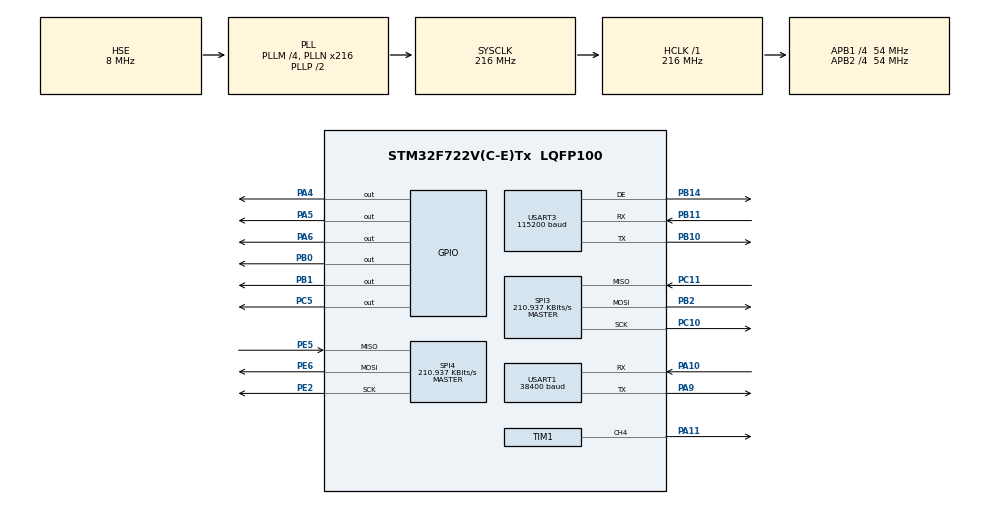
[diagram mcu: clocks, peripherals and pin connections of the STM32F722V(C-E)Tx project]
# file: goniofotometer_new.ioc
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Dma.Request0=USART3_RX
Dma.Request1=USART1_RX
Dma.Request2=SPI4_RX
Dma.Request3=SPI4_TX
Dma.Request4=SPI3_RX
Dma.Request5=SPI3_TX
Dma.SPI3_RX.4.Direction=DMA_PERIPH_TO_MEMORY
Dma.SPI3_RX.4.FIFOMode=DMA_FIFOMODE_DISABLE
Dma.SPI3_RX.4.Instance=DMA1_Stream0
Dma.SPI3_RX.4.MemDataAlignment=DMA_MDATAALIGN_BYTE
Dma.SPI3_RX.4.MemInc=DMA_MINC_ENABLE
Dma.SPI3_RX.4.Mode=DMA_NORMAL
Dma.SPI3_RX.4.PeriphDataAlignment=DMA_PDATAALIGN_BYTE
Dma.SPI3_RX.4.PeriphInc=DMA_PINC_DISABLE
Dma.SPI3_RX.4.Priority=DMA_PRIORITY_LOW
Dma.SPI3_TX.5.Direction=DMA_MEMORY_TO_PERIPH
Dma.SPI3_TX.5.FIFOMode=DMA_FIFOMODE_DISABLE
Dma.SPI3_TX.5.Instance=DMA1_Stream5
Dma.SPI3_TX.5.MemDataAlignment=DMA_MDATAALIGN_BYTE
Dma.SPI3_TX.5.MemInc=DMA_MINC_ENABLE
Dma.SPI3_TX.5.Mode=DMA_NORMAL
Dma.SPI3_TX.5.PeriphDataAlignment=DMA_PDATAALIGN_BYTE
Dma.SPI3_TX.5.PeriphInc=DMA_PINC_DISABLE
Dma.SPI3_TX.5.Priority=DMA_PRIORITY_LOW
Dma.SPI4_RX.2.Direction=DMA_PERIPH_TO_MEMORY
Dma.SPI4_RX.2.FIFOMode=DMA_FIFOMODE_DISABLE
Dma.SPI4_RX.2.Instance=DMA2_Stream0
Dma.SPI4_RX.2.MemDataAlignment=DMA_MDATAALIGN_BYTE
Dma.SPI4_RX.2.MemInc=DMA_MINC_ENABLE
Dma.SPI4_RX.2.Mode=DMA_NORMAL
Dma.SPI4_RX.2.PeriphDataAlignment=DMA_PDATAALIGN_BYTE
Dma.SPI4_RX.2.PeriphInc=DMA_PINC_DISABLE
Dma.SPI4_RX.2.Priority=DMA_PRIORITY_LOW
Dma.SPI4_TX.3.Direction=DMA_MEMORY_TO_PERIPH
Dma.SPI4_TX.3.FIFOMode=DMA_FIFOMODE_DISABLE
Dma.SPI4_TX.3.Instance=DMA2_Stream1
Dma.SPI4_TX.3.MemDataAlignment=DMA_MDATAALIGN_BYTE
Dma.SPI4_TX.3.MemInc=DMA_MINC_ENABLE
Dma.SPI4_TX.3.Mode=DMA_NORMAL
Dma.SPI4_TX.3.PeriphDataAlignment=DMA_PDATAALIGN_BYTE
Dma.SPI4_TX.3.PeriphInc=DMA_PINC_DISABLE
Dma.SPI4_TX.3.Priority=DMA_PRIORITY_LOW
Dma.USART1_RX.1.Direction=DMA_PERIPH_TO_MEMORY
Dma.USART1_RX.1.FIFOMode=DMA_FIFOMODE_DISABLE
Dma.USART1_RX.1.Instance=DMA2_Stream2
Dma.USART1_RX.1.MemDataAlignment=DMA_MDATAALIGN_BYTE
Dma.USART1_RX.1.MemInc=DMA_MINC_ENABLE
Dma.USART1_RX.1.Mode=DMA_NORMAL
Dma.USART1_RX.1.PeriphDataAlignment=DMA_PDATAALIGN_BYTE
Dma.USART1_RX.1.PeriphInc=DMA_PINC_DISABLE
Dma.USART1_RX.1.Priority=DMA_PRIORITY_HIGH
Dma.USART3_RX.0.Direction=DMA_PERIPH_TO_MEMORY
Dma.USART3_RX.0.FIFOMode=DMA_FIFOMODE_DISABLE
Dma.USART3_RX.0.Instance=DMA1_Stream1
Dma.USART3_RX.0.MemDataAlignment=DMA_MDATAALIGN_BYTE
Dma.USART3_RX.0.MemInc=DMA_MINC_ENABLE
Dma.USART3_RX.0.Mode=DMA_CIRCULAR
Dma.USART3_RX.0.PeriphDataAlignment=DMA_PDATAALIGN_BYTE
Dma.USART3_RX.0.PeriphInc=DMA_PINC_DISABLE
Dma.USART3_RX.0.Priority=DMA_PRIORITY_LOW
IWDG.Prescaler=IWDG_PRESCALER_16
Mcu.Family=STM32F7
Mcu.Name=STM32F722V(C-E)Tx
Mcu.Package=LQFP100
NVIC.DMA1_Stream0_IRQn=true\:1\:0\:true\:false\:true\:false\:true\:true
NVIC.DMA1_Stream1_IRQn=true\:1\:0\:true\:false\:true\:false\:true\:true
NVIC.DMA1_Stream5_IRQn=true\:1\:0\:true\:false\:true\:false\:true\:true
NVIC.DMA2_Stream0_IRQn=true\:1\:1\:true\:false\:true\:false\:true\:true
NVIC.DMA2_Stream1_IRQn=true\:1\:1\:true\:false\:true\:false\:true\:true
NVIC.DMA2_Stream2_IRQn=true\:1\:0\:true\:false\:true\:false\:true\:true
NVIC.PriorityGroup=NVIC_PRIORITYGROUP_2
NVIC.TIM1_TRG_COM_TIM11_IRQn=true\:1\:3\:true\:false\:true\:true\:true\:true
NVIC.TIM1_UP_TIM10_IRQn=true\:3\:3\:true\:false\:true\:true\:true\:true
NVIC.TIM2_IRQn=true\:2\:0\:true\:false\:true\:true\:true\:true
NVIC.TIM3_IRQn=true\:2\:0\:true\:false\:true\:true\:true\:true
NVIC.TIM4_IRQn=true\:0\:0\:false\:false\:true\:true\:true\:true
NVIC.TIM5_IRQn=true\:1\:0\:true\:false\:true\:true\:true\:true
NVIC.TIM7_IRQn=true\:2\:0\:true\:false\:true\:true\:true\:true
NVIC.TIM8_BRK_TIM12_IRQn=true\:1\:3\:true\:false\:true\:true\:true\:true
NVIC.TIM8_TRG_COM_TIM14_IRQn=true\:1\:1\:true\:false\:true\:true\:true\:true
NVIC.TIM8_UP_TIM13_IRQn=true\:1\:1\:true\:false\:true\:true\:true\:true
NVIC.USART1_IRQn=true\:1\:0\:true\:false\:true\:true\:true\:true
NVIC.USART3_IRQn=true\:1\:0\:true\:false\:true\:true\:true\:true
PA10.Mode=Asynchronous
PA10.Signal=USART1_RX
PA11.Signal=S_TIM1_CH4
PA13.Mode=Serial_Wire
PA13.Signal=SYS_JTMS-SWDIO
PA14.Mode=Serial_Wire
PA14.Signal=SYS_JTCK-SWCLK
PA4.Signal=GPIO_Output
PA5.Signal=GPIO_Output
PA6.Signal=GPIO_Output
PA9.Mode=Asynchronous
PA9.Signal=USART1_TX
PB0.Signal=GPIO_Output
PB1.Signal=GPIO_Output
PB10.Mode=Asynchronous
PB10.Signal=USART3_TX
PB11.Mode=Asynchronous
PB11.Signal=USART3_RX
PB14.Mode=Hardware Flow Control (RS485)
PB14.Signal=USART3_DE
PB2.Mode=Full_Duplex_Master
PB2.Signal=SPI3_MOSI
PC10.Mode=Full_Duplex_Master
PC10.Signal=SPI3_SCK
PC11.Mode=Full_Duplex_Master
PC11.Signal=SPI3_MISO
PC5.Signal=GPIO_Output
PE2.Mode=Full_Duplex_Master
PE2.Signal=SPI4_SCK
PE5.Mode=Full_Duplex_Master
PE5.Signal=SPI4_MISO
PE6.Mode=Full_Duplex_Master
PE6.Signal=SPI4_MOSI
PH0-OSC_IN.Mode=HSE-External-Oscillator
PH0-OSC_IN.Signal=RCC_OSC_IN
PH1-OSC_OUT.Mode=HSE-External-Oscillator
PH1-OSC_OUT.Signal=RCC_OSC_OUT
ProjectManager.HeapSize=0x200
ProjectManager.StackSize=0x400
ProjectManager.TargetToolchain=STM32CubeIDE
RCC.AHBFreq_Value=216000000
RCC.APB1CLKDivider=RCC_HCLK_DIV4
RCC.APB1Freq_Value=54000000
RCC.APB1TimFreq_Value=108000000
RCC.APB2CLKDivider=RCC_HCLK_DIV4
RCC.APB2Freq_Value=54000000
RCC.APB2TimFreq_Value=108000000
RCC.CortexFreq_Value=216000000
RCC.HCLKFreq_Value=216000000
RCC.HSE_VALUE=8000000
RCC.HSI_VALUE=16000000
RCC.LSE_VALUE=32768
RCC.PLLM=4
RCC.PLLN=216
RCC.PLLSourceVirtual=RCC_PLLSOURCE_HSE
RCC.SYSCLKFreq_VALUE=216000000
RCC.SYSCLKSource=RCC_SYSCLKSOURCE_PLLCLK
RCC.USBFreq_Value=216000000
RCC.VCOOutputFreq_Value=432000000
SH.S_TIM1_CH4.0=TIM1_CH4,PWM Generation4 CH4
SPI3.BaudRatePrescaler=SPI_BAUDRATEPRESCALER_256
SPI3.CLKPolarity=SPI_POLARITY_HIGH
SPI3.CalculateBaudRate=210.937 KBits/s
SPI3.DataSize=SPI_DATASIZE_8BIT
SPI3.Direction=SPI_DIRECTION_2LINES
SPI3.Mode=SPI_MODE_MASTER
SPI3.VirtualType=VM_MASTER
SPI4.BaudRatePrescaler=SPI_BAUDRATEPRESCALER_256
SPI4.CLKPolarity=SPI_POLARITY_HIGH
SPI4.CalculateBaudRate=210.937 KBits/s
SPI4.DataSize=SPI_DATASIZE_8BIT
SPI4.Direction=SPI_DIRECTION_2LINES
SPI4.Mode=SPI_MODE_MASTER
SPI4.VirtualType=VM_MASTER
TIM1.Channel-PWM\ Generation4\ CH4=TIM_CHANNEL_4
TIM1.OCPolarity_4=TIM_OCPOLARITY_LOW
TIM1.Period=21
TIM1.Prescaler=107
TIM1.Pulse-PWM\ Generation4\ CH4=1
TIM10.Period=65535
TIM10.Prescaler=21599
TIM11.Period=30000
TIM11.Prescaler=10799
TIM12.Period=500
TIM12.Prescaler=10799
TIM13.Prescaler=1079
TIM14.Prescaler=21599
TIM2.Period=24999
TIM2.Prescaler=107
TIM3.Period=15999
TIM3.Prescaler=1079
TIM4.Period=200
TIM4.Prescaler=10799
TIM5.Prescaler=10799
TIM6.Prescaler=107
TIM7.Period=99
TIM7.Prescaler=107
USART1.BaudRate=38400
USART1.VirtualMode-Asynchronous=VM_ASYNC
USART3.BaudRate=115200
USART3.VirtualMode-Asynchronous=VM_ASYNC
USART3.VirtualMode-Hardware\ Flow\ Control\ (RS485)=VM_ASYNC
VP_IWDG_VS_IWDG.Mode=IWDG_Activate
VP_TIM10_VS_ClockSourceINT.Mode=Enable_Timer
VP_TIM11_VS_ClockSourceINT.Mode=Enable_Timer
VP_TIM12_VS_ClockSourceINT.Mode=Internal
VP_TIM13_VS_ClockSourceINT.Mode=Enable_Timer
VP_TIM14_VS_ClockSourceINT.Mode=Enable_Timer
VP_TIM1_VS_ClockSourceINT.Mode=Internal
VP_TIM1_VS_OPM.Mode=OPM_bit
VP_TIM2_VS_ClockSourceINT.Mode=Internal
VP_TIM3_VS_ClockSourceINT.Mode=Internal
VP_TIM4_VS_ClockSourceINT.Mode=Internal
VP_TIM5_VS_ClockSourceINT.Mode=Internal
VP_TIM6_VS_ClockSourceINT.Mode=Enable_Timer
VP_TIM7_VS_ClockSourceINT.Mode=Enable_Timer
board=custom

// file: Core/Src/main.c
/* USER CODE BEGIN Header */
/**
  ******************************************************************************
  * @file           : main.c
  * @brief          : Main program body
  ******************************************************************************
  * @attention
  *
  * Copyright (c) 2026 STMicroelectronics.
  * All rights reserved.
  *
  * This software is licensed under terms that can be found in the LICENSE file
  * in the root directory of this software component.
  * If no LICENSE file comes with this software, it is provided AS-IS.
  *
  ******************************************************************************
  */
/* USER CODE END Header */
#include "main.h"

/* USER CODE BEGIN Includes */
#include "Common.h"
#include "FSMGonio.h"
/* USER CODE END Includes */

IWDG_HandleTypeDef hiwdg;

SPI_HandleTypeDef hspi3;
SPI_HandleTypeDef hspi4;
DMA_HandleTypeDef hdma_spi3_rx;
DMA_HandleTypeDef hdma_spi3_tx;
DMA_HandleTypeDef hdma_spi4_rx;
DMA_HandleTypeDef hdma_spi4_tx;

TIM_HandleTypeDef htim1;
TIM_HandleTypeDef htim2;
TIM_HandleTypeDef htim3;
TIM_HandleTypeDef htim4;
TIM_HandleTypeDef htim5;
TIM_HandleTypeDef htim6;
TIM_HandleTypeDef htim7;
TIM_HandleTypeDef htim10;
TIM_HandleTypeDef htim11;
TIM_HandleTypeDef htim12;
TIM_HandleTypeDef htim13;
TIM_HandleTypeDef htim14;

UART_HandleTypeDef huart1;
UART_HandleTypeDef huart3;
DMA_HandleTypeDef hdma_usart1_rx;
DMA_HandleTypeDef hdma_usart3_rx;

void SystemClock_Config(void);
static void MX_GPIO_Init(void);
static void MX_DMA_Init(void);
static void MX_USART3_UART_Init(void);
static void MX_USART1_UART_Init(void);
static void MX_SPI4_Init(void);
static void MX_SPI3_Init(void);
static void MX_TIM2_Init(void);
static void MX_TIM3_Init(void);
static void MX_TIM6_Init(void);
static void MX_TIM7_Init(void);
static void MX_TIM10_Init(void);
static void MX_TIM5_Init(void);
static void MX_TIM14_Init(void);
static void MX_TIM13_Init(void);
static void MX_TIM4_Init(void);
static void MX_TIM11_Init(void);
static void MX_TIM12_Init(void);
static void MX_IWDG_Init(void);
static void MX_TIM1_Init(void);

/* USER CODE BEGIN 0 */
void resetWatchDogTimer() {
	HAL_IWDG_Refresh(&hiwdg);
}
/* USER CODE END 0 */

int main(void)
{

  /* MCU Configuration--------------------------------------------------------*/

  /* Reset of all peripherals, Initializes the Flash interface and the Systick. */
  HAL_Init();

  /* Configure the system clock */
  SystemClock_Config();

  /* Initialize all configured peripherals */
  MX_GPIO_Init();
  MX_DMA_Init();
  MX_USART3_UART_Init();
  MX_USART1_UART_Init();
  MX_SPI4_Init();
  MX_SPI3_Init();
  MX_TIM2_Init();
  MX_TIM3_Init();
  MX_TIM6_Init();
  MX_TIM7_Init();
  MX_TIM10_Init();
  MX_TIM5_Init();
  MX_TIM14_Init();
  MX_TIM13_Init();
  MX_TIM4_Init();
  MX_TIM11_Init();
  MX_TIM12_Init();
  MX_IWDG_Init();
  MX_TIM1_Init();
  /* USER CODE BEGIN 2 */
  initFSMGonio();
  /* USER CODE END 2 */

  /* Infinite loop */
  /* USER CODE BEGIN WHILE */
  while (1)
  {
	// обновление сторожевого таймера
	resetWatchDogTimer();

	// вход в диспетчер машины состояний
	dispatchFSMGlobal();

	// проверка keep-alive таймера
	if (tim11_ovflw) {
		resetGonio();
		tim11_ovflw = 0;
	}

    /* USER CODE END WHILE */

  }
}

void SystemClock_Config(void)
{
  RCC_OscInitTypeDef RCC_OscInitStruct = {0};
  RCC_ClkInitTypeDef RCC_ClkInitStruct = {0};

  /** Configure the main internal regulator output voltage
  */
  __HAL_RCC_PWR_CLK_ENABLE();
  __HAL_PWR_VOLTAGESCALING_CONFIG(PWR_REGULATOR_VOLTAGE_SCALE1);

  /** Initializes the RCC Oscillators according to the specified parameters
  * in the RCC_OscInitTypeDef structure.
  */
  RCC_OscInitStruct.OscillatorType = RCC_OSCILLATORTYPE_LSI|RCC_OSCILLATORTYPE_HSE;
  RCC_OscInitStruct.HSEState = RCC_HSE_ON;
  RCC_OscInitStruct.LSIState = RCC_LSI_ON;
  RCC_OscInitStruct.PLL.PLLState = RCC_PLL_ON;
  RCC_OscInitStruct.PLL.PLLSource = RCC_PLLSOURCE_HSE;
  RCC_OscInitStruct.PLL.PLLM = 4;
  RCC_OscInitStruct.PLL.PLLN = 216;
  RCC_OscInitStruct.PLL.PLLP = RCC_PLLP_DIV2;
  RCC_OscInitStruct.PLL.PLLQ = 2;
  if (HAL_RCC_OscConfig(&RCC_OscInitStruct) != HAL_OK)
  {
    Error_Handler();
  }

  /** Activate the Over-Drive mode
  */
  if (HAL_PWREx_EnableOverDrive() != HAL_OK)
  {
    Error_Handler();
  }

  /** Initializes the CPU, AHB and APB buses clocks
  */
  RCC_ClkInitStruct.ClockType = RCC_CLOCKTYPE_HCLK|RCC_CLOCKTYPE_SYSCLK
                              |RCC_CLOCKTYPE_PCLK1|RCC_CLOCKTYPE_PCLK2;
  RCC_ClkInitStruct.SYSCLKSource = RCC_SYSCLKSOURCE_PLLCLK;
  RCC_ClkInitStruct.AHBCLKDivider = RCC_SYSCLK_DIV1;
  RCC_ClkInitStruct.APB1CLKDivider = RCC_HCLK_DIV4;
  RCC_ClkInitStruct.APB2CLKDivider = RCC_HCLK_DIV4;

  if (HAL_RCC_ClockConfig(&RCC_ClkInitStruct, FLASH_LATENCY_7) != HAL_OK)
  {
    Error_Handler();
  }
}

static void MX_IWDG_Init(void)
{

  hiwdg.Instance = IWDG;
  hiwdg.Init.Prescaler = IWDG_PRESCALER_16;
  hiwdg.Init.Window = 4095;
  hiwdg.Init.Reload = 4095;
  if (HAL_IWDG_Init(&hiwdg) != HAL_OK)
  {
    Error_Handler();
  }

}

static void MX_SPI3_Init(void)
{

  /* SPI3 parameter configuration*/
  hspi3.Instance = SPI3;
  hspi3.Init.Mode = SPI_MODE_MASTER;
  hspi3.Init.Direction = SPI_DIRECTION_2LINES;
  hspi3.Init.DataSize = SPI_DATASIZE_8BIT;
  hspi3.Init.CLKPolarity = SPI_POLARITY_HIGH;
  hspi3.Init.CLKPhase = SPI_PHASE_1EDGE;
  hspi3.Init.NSS = SPI_NSS_SOFT;
  hspi3.Init.BaudRatePrescaler = SPI_BAUDRATEPRESCALER_256;
  hspi3.Init.FirstBit = SPI_FIRSTBIT_MSB;
  hspi3.Init.TIMode = SPI_TIMODE_DISABLE;
  hspi3.Init.CRCCalculation = SPI_CRCCALCULATION_DISABLE;
  hspi3.Init.CRCPolynomial = 7;
  hspi3.Init.CRCLength = SPI_CRC_LENGTH_DATASIZE;
  hspi3.Init.NSSPMode = SPI_NSS_PULSE_ENABLE;
  if (HAL_SPI_Init(&hspi3) != HAL_OK)
  {
    Error_Handler();
  }

}

static void MX_SPI4_Init(void)
{

  /* SPI4 parameter configuration*/
  hspi4.Instance = SPI4;
  hspi4.Init.Mode = SPI_MODE_MASTER;
  hspi4.Init.Direction = SPI_DIRECTION_2LINES;
  hspi4.Init.DataSize = SPI_DATASIZE_8BIT;
  hspi4.Init.CLKPolarity = SPI_POLARITY_HIGH;
  hspi4.Init.CLKPhase = SPI_PHASE_1EDGE;
  hspi4.Init.NSS = SPI_NSS_SOFT;
  hspi4.Init.BaudRatePrescaler = SPI_BAUDRATEPRESCALER_256;
  hspi4.Init.FirstBit = SPI_FIRSTBIT_MSB;
  hspi4.Init.TIMode = SPI_TIMODE_DISABLE;
  hspi4.Init.CRCCalculation = SPI_CRCCALCULATION_DISABLE;
  hspi4.Init.CRCPolynomial = 7;
  hspi4.Init.CRCLength = SPI_CRC_LENGTH_DATASIZE;
  hspi4.Init.NSSPMode = SPI_NSS_PULSE_ENABLE;
  if (HAL_SPI_Init(&hspi4) != HAL_OK)
  {
    Error_Handler();
  }

}

static void MX_TIM1_Init(void)
{

  TIM_ClockConfigTypeDef sClockSourceConfig = {0};
  TIM_MasterConfigTypeDef sMasterConfig = {0};
  TIM_OC_InitTypeDef sConfigOC = {0};
  TIM_BreakDeadTimeConfigTypeDef sBreakDeadTimeConfig = {0};

  htim1.Instance = TIM1;
  htim1.Init.Prescaler = 107;
  htim1.Init.CounterMode = TIM_COUNTERMODE_UP;
  htim1.Init.Period = 21;
  htim1.Init.ClockDivision = TIM_CLOCKDIVISION_DIV1;
  htim1.Init.RepetitionCounter = 0;
  htim1.Init.AutoReloadPreload = TIM_AUTORELOAD_PRELOAD_DISABLE;
  if (HAL_TIM_Base_Init(&htim1) != HAL_OK)
  {
    Error_Handler();
  }
  sClockSourceConfig.ClockSource = TIM_CLOCKSOURCE_INTERNAL;
  if (HAL_TIM_ConfigClockSource(&htim1, &sClockSourceConfig) != HAL_OK)
  {
    Error_Handler();
  }
  if (HAL_TIM_PWM_Init(&htim1) != HAL_OK)
  {
    Error_Handler();
  }
  if (HAL_TIM_OnePulse_Init(&htim1, TIM_OPMODE_SINGLE) != HAL_OK)
  {
    Error_Handler();
  }
  sMasterConfig.MasterOutputTrigger = TIM_TRGO_RESET;
  sMasterConfig.MasterOutputTrigger2 = TIM_TRGO2_RESET;
  sMasterConfig.MasterSlaveMode = TIM_MASTERSLAVEMODE_DISABLE;
  if (HAL_TIMEx_MasterConfigSynchronization(&htim1, &sMasterConfig) != HAL_OK)
  {
    Error_Handler();
  }
  sConfigOC.OCMode = TIM_OCMODE_PWM1;
  sConfigOC.Pulse = 1;
  sConfigOC.OCPolarity = TIM_OCPOLARITY_LOW;
  sConfigOC.OCFastMode = TIM_OCFAST_DISABLE;
  sConfigOC.OCIdleState = TIM_OCIDLESTATE_RESET;
  sConfigOC.OCNIdleState = TIM_OCNIDLESTATE_RESET;
  if (HAL_TIM_PWM_ConfigChannel(&htim1, &sConfigOC, TIM_CHANNEL_4) != HAL_OK)
  {
    Error_Handler();
  }
  sBreakDeadTimeConfig.OffStateRunMode = TIM_OSSR_DISABLE;
  sBreakDeadTimeConfig.OffStateIDLEMode = TIM_OSSI_DISABLE;
  sBreakDeadTimeConfig.LockLevel = TIM_LOCKLEVEL_OFF;
  sBreakDeadTimeConfig.DeadTime = 0;
  sBreakDeadTimeConfig.BreakState = TIM_BREAK_DISABLE;
  sBreakDeadTimeConfig.BreakPolarity = TIM_BREAKPOLARITY_HIGH;
  sBreakDeadTimeConfig.BreakFilter = 0;
  sBreakDeadTimeConfig.Break2State = TIM_BREAK2_DISABLE;
  sBreakDeadTimeConfig.Break2Polarity = TIM_BREAK2POLARITY_HIGH;
  sBreakDeadTimeConfig.Break2Filter = 0;
  sBreakDeadTimeConfig.AutomaticOutput = TIM_AUTOMATICOUTPUT_DISABLE;
  if (HAL_TIMEx_ConfigBreakDeadTime(&htim1, &sBreakDeadTimeConfig) != HAL_OK)
  {
    Error_Handler();
  }
  HAL_TIM_MspPostInit(&htim1);

}

static void MX_TIM2_Init(void)
{

  TIM_ClockConfigTypeDef sClockSourceConfig = {0};
  TIM_MasterConfigTypeDef sMasterConfig = {0};

  htim2.Instance = TIM2;
  htim2.Init.Prescaler = 107;
  htim2.Init.CounterMode = TIM_COUNTERMODE_UP;
  htim2.Init.Period = 24999;
  htim2.Init.ClockDivision = TIM_CLOCKDIVISION_DIV1;
  htim2.Init.AutoReloadPreload = TIM_AUTORELOAD_PRELOAD_DISABLE;
  if (HAL_TIM_Base_Init(&htim2) != HAL_OK)
  {
    Error_Handler();
  }
  sClockSourceConfig.ClockSource = TIM_CLOCKSOURCE_INTERNAL;
  if (HAL_TIM_ConfigClockSource(&htim2, &sClockSourceConfig) != HAL_OK)
  {
    Error_Handler();
  }
  sMasterConfig.MasterOutputTrigger = TIM_TRGO_RESET;
  sMasterConfig.MasterSlaveMode = TIM_MASTERSLAVEMODE_DISABLE;
  if (HAL_TIMEx_MasterConfigSynchronization(&htim2, &sMasterConfig) != HAL_OK)
  {
    Error_Handler();
  }

}

static void MX_TIM3_Init(void)
{

  TIM_ClockConfigTypeDef sClockSourceConfig = {0};
  TIM_MasterConfigTypeDef sMasterConfig = {0};

  htim3.Instance = TIM3;
  htim3.Init.Prescaler = 1079;
  htim3.Init.CounterMode = TIM_COUNTERMODE_UP;
  htim3.Init.Period = 15999;
  htim3.Init.ClockDivision = TIM_CLOCKDIVISION_DIV1;
  htim3.Init.AutoReloadPreload = TIM_AUTORELOAD_PRELOAD_DISABLE;
  if (HAL_TIM_Base_Init(&htim3) != HAL_OK)
  {
    Error_Handler();
  }
  sClockSourceConfig.ClockSource = TIM_CLOCKSOURCE_INTERNAL;
  if (HAL_TIM_ConfigClockSource(&htim3, &sClockSourceConfig) != HAL_OK)
  {
    Error_Handler();
  }
  sMasterConfig.MasterOutputTrigger = TIM_TRGO_RESET;
  sMasterConfig.MasterSlaveMode = TIM_MASTERSLAVEMODE_DISABLE;
  if (HAL_TIMEx_MasterConfigSynchronization(&htim3, &sMasterConfig) != HAL_OK)
  {
    Error_Handler();
  }

}

static void MX_TIM4_Init(void)
{

  TIM_ClockConfigTypeDef sClockSourceConfig = {0};
  TIM_MasterConfigTypeDef sMasterConfig = {0};

  htim4.Instance = TIM4;
  htim4.Init.Prescaler = 10799;
  htim4.Init.CounterMode = TIM_COUNTERMODE_UP;
  htim4.Init.Period = 200;
  htim4.Init.ClockDivision = TIM_CLOCKDIVISION_DIV1;
  htim4.Init.AutoReloadPreload = TIM_AUTORELOAD_PRELOAD_DISABLE;
  if (HAL_TIM_Base_Init(&htim4) != HAL_OK)
  {
    Error_Handler();
  }
  sClockSourceConfig.ClockSource = TIM_CLOCKSOURCE_INTERNAL;
  if (HAL_TIM_ConfigClockSource(&htim4, &sClockSourceConfig) != HAL_OK)
  {
    Error_Handler();
  }
  sMasterConfig.MasterOutputTrigger = TIM_TRGO_RESET;
  sMasterConfig.MasterSlaveMode = TIM_MASTERSLAVEMODE_DISABLE;
  if (HAL_TIMEx_MasterConfigSynchronization(&htim4, &sMasterConfig) != HAL_OK)
  {
    Error_Handler();
  }

}

static void MX_TIM5_Init(void)
{

  TIM_ClockConfigTypeDef sClockSourceConfig = {0};
  TIM_MasterConfigTypeDef sMasterConfig = {0};

  htim5.Instance = TIM5;
  htim5.Init.Prescaler = 10799;
  htim5.Init.CounterMode = TIM_COUNTERMODE_UP;
  htim5.Init.Period = 4294967295;
  htim5.Init.ClockDivision = TIM_CLOCKDIVISION_DIV1;
  htim5.Init.AutoReloadPreload = TIM_AUTORELOAD_PRELOAD_DISABLE;
  if (HAL_TIM_Base_Init(&htim5) != HAL_OK)
  {
    Error_Handler();
  }
  sClockSourceConfig.ClockSource = TIM_CLOCKSOURCE_INTERNAL;
  if (HAL_TIM_ConfigClockSource(&htim5, &sClockSourceConfig) != HAL_OK)
  {
    Error_Handler();
  }
  sMasterConfig.MasterOutputTrigger = TIM_TRGO_RESET;
  sMasterConfig.MasterSlaveMode = TIM_MASTERSLAVEMODE_DISABLE;
  if (HAL_TIMEx_MasterConfigSynchronization(&htim5, &sMasterConfig) != HAL_OK)
  {
    Error_Handler();
  }

}

static void MX_TIM6_Init(void)
{

  TIM_MasterConfigTypeDef sMasterConfig = {0};

  htim6.Instance = TIM6;
  htim6.Init.Prescaler = 107;
  htim6.Init.CounterMode = TIM_COUNTERMODE_UP;
  htim6.Init.Period = 65535;
  htim6.Init.AutoReloadPreload = TIM_AUTORELOAD_PRELOAD_DISABLE;
  if (HAL_TIM_Base_Init(&htim6) != HAL_OK)
  {
    Error_Handler();
  }
  sMasterConfig.MasterOutputTrigger = TIM_TRGO_RESET;
  sMasterConfig.MasterSlaveMode = TIM_MASTERSLAVEMODE_DISABLE;
  if (HAL_TIMEx_MasterConfigSynchronization(&htim6, &sMasterConfig) != HAL_OK)
  {
    Error_Handler();
  }

}

static void MX_TIM7_Init(void)
{

  TIM_MasterConfigTypeDef sMasterConfig = {0};

  htim7.Instance = TIM7;
  htim7.Init.Prescaler = 107;
  htim7.Init.CounterMode = TIM_COUNTERMODE_UP;
  htim7.Init.Period = 99;
  htim7.Init.AutoReloadPreload = TIM_AUTORELOAD_PRELOAD_DISABLE;
  if (HAL_TIM_Base_Init(&htim7) != HAL_OK)
  {
    Error_Handler();
  }
  sMasterConfig.MasterOutputTrigger = TIM_TRGO_RESET;
  sMasterConfig.MasterSlaveMode = TIM_MASTERSLAVEMODE_DISABLE;
  if (HAL_TIMEx_MasterConfigSynchronization(&htim7, &sMasterConfig) != HAL_OK)
  {
    Error_Handler();
  }

}

static void MX_TIM10_Init(void)
{

  htim10.Instance = TIM10;
  htim10.Init.Prescaler = 21599;
  htim10.Init.CounterMode = TIM_COUNTERMODE_UP;
  htim10.Init.Period = 65535;
  htim10.Init.ClockDivision = TIM_CLOCKDIVISION_DIV1;
  htim10.Init.AutoReloadPreload = TIM_AUTORELOAD_PRELOAD_DISABLE;
  if (HAL_TIM_Base_Init(&htim10) != HAL_OK)
  {
    Error_Handler();
  }

}

static void MX_TIM11_Init(void)
{

  htim11.Instance = TIM11;
  htim11.Init.Prescaler = 10799;
  htim11.Init.CounterMode = TIM_COUNTERMODE_UP;
  htim11.Init.Period = 30000;
  htim11.Init.ClockDivision = TIM_CLOCKDIVISION_DIV1;
  htim11.Init.AutoReloadPreload = TIM_AUTORELOAD_PRELOAD_DISABLE;
  if (HAL_TIM_Base_Init(&htim11) != HAL_OK)
  {
    Error_Handler();
  }

}

static void MX_TIM12_Init(void)
{

  TIM_ClockConfigTypeDef sClockSourceConfig = {0};

  htim12.Instance = TIM12;
  htim12.Init.Prescaler = 10799;
  htim12.Init.CounterMode = TIM_COUNTERMODE_UP;
  htim12.Init.Period = 500;
  htim12.Init.ClockDivision = TIM_CLOCKDIVISION_DIV1;
  htim12.Init.AutoReloadPreload = TIM_AUTORELOAD_PRELOAD_DISABLE;
  if (HAL_TIM_Base_Init(&htim12) != HAL_OK)
  {
    Error_Handler();
  }
  sClockSourceConfig.ClockSource = TIM_CLOCKSOURCE_INTERNAL;
  if (HAL_TIM_ConfigClockSource(&htim12, &sClockSourceConfig) != HAL_OK)
  {
    Error_Handler();
  }

}

static void MX_TIM13_Init(void)
{

  htim13.Instance = TIM13;
  htim13.Init.Prescaler = 1079;
  htim13.Init.CounterMode = TIM_COUNTERMODE_UP;
  htim13.Init.Period = 65535;
  htim13.Init.ClockDivision = TIM_CLOCKDIVISION_DIV1;
  htim13.Init.AutoReloadPreload = TIM_AUTORELOAD_PRELOAD_DISABLE;
  if (HAL_TIM_Base_Init(&htim13) != HAL_OK)
  {
    Error_Handler();
  }

}

static void MX_TIM14_Init(void)
{

  htim14.Instance = TIM14;
  htim14.Init.Prescaler = 21599;
  htim14.Init.CounterMode = TIM_COUNTERMODE_UP;
  htim14.Init.Period = 65535;
  htim14.Init.ClockDivision = TIM_CLOCKDIVISION_DIV1;
  htim14.Init.AutoReloadPreload = TIM_AUTORELOAD_PRELOAD_DISABLE;
  if (HAL_TIM_Base_Init(&htim14) != HAL_OK)
  {
    Error_Handler();
  }

}

static void MX_USART1_UART_Init(void)
{

  huart1.Instance = USART1;
  huart1.Init.BaudRate = 38400;
  huart1.Init.WordLength = UART_WORDLENGTH_8B;
  huart1.Init.StopBits = UART_STOPBITS_1;
  huart1.Init.Parity = UART_PARITY_NONE;
  huart1.Init.Mode = UART_MODE_TX_RX;
  huart1.Init.HwFlowCtl = UART_HWCONTROL_NONE;
  huart1.Init.OverSampling = UART_OVERSAMPLING_16;
  huart1.Init.OneBitSampling = UART_ONE_BIT_SAMPLE_DISABLE;
  huart1.AdvancedInit.AdvFeatureInit = UART_ADVFEATURE_NO_INIT;
  if (HAL_UART_Init(&huart1) != HAL_OK)
  {
    Error_Handler();
  }

}

static void MX_USART3_UART_Init(void)
{

  huart3.Instance = USART3;
  huart3.Init.BaudRate = 115200;
  huart3.Init.WordLength = UART_WORDLENGTH_8B;
  huart3.Init.StopBits = UART_STOPBITS_1;
  huart3.Init.Parity = UART_PARITY_NONE;
  huart3.Init.Mode = UART_MODE_TX_RX;
  huart3.Init.HwFlowCtl = UART_HWCONTROL_NONE;
  huart3.Init.OverSampling = UART_OVERSAMPLING_16;
  huart3.Init.OneBitSampling = UART_ONE_BIT_SAMPLE_DISABLE;
  huart3.AdvancedInit.AdvFeatureInit = UART_ADVFEATURE_NO_INIT;
  if (HAL_RS485Ex_Init(&huart3, UART_DE_POLARITY_HIGH, 0, 0) != HAL_OK)
  {
    Error_Handler();
  }

}

static void MX_DMA_Init(void)
{

  /* DMA controller clock enable */
  __HAL_RCC_DMA1_CLK_ENABLE();
  __HAL_RCC_DMA2_CLK_ENABLE();

  /* DMA interrupt init */
  /* DMA1_Stream0_IRQn interrupt configuration */
  HAL_NVIC_SetPriority(DMA1_Stream0_IRQn, 1, 0);
  HAL_NVIC_EnableIRQ(DMA1_Stream0_IRQn);
  /* DMA1_Stream1_IRQn interrupt configuration */
  HAL_NVIC_SetPriority(DMA1_Stream1_IRQn, 1, 0);
  HAL_NVIC_EnableIRQ(DMA1_Stream1_IRQn);
  /* DMA1_Stream5_IRQn interrupt configuration */
  HAL_NVIC_SetPriority(DMA1_Stream5_IRQn, 1, 0);
  HAL_NVIC_EnableIRQ(DMA1_Stream5_IRQn);
  /* DMA2_Stream0_IRQn interrupt configuration */
  HAL_NVIC_SetPriority(DMA2_Stream0_IRQn, 1, 1);
  HAL_NVIC_EnableIRQ(DMA2_Stream0_IRQn);
  /* DMA2_Stream1_IRQn interrupt configuration */
  HAL_NVIC_SetPriority(DMA2_Stream1_IRQn, 1, 1);
  HAL_NVIC_EnableIRQ(DMA2_Stream1_IRQn);
  /* DMA2_Stream2_IRQn interrupt configuration */
  HAL_NVIC_SetPriority(DMA2_Stream2_IRQn, 1, 0);
  HAL_NVIC_EnableIRQ(DMA2_Stream2_IRQn);

}

static void MX_GPIO_Init(void)
{
  GPIO_InitTypeDef GPIO_InitStruct = {0};

  /* GPIO Ports Clock Enable */
  __HAL_RCC_GPIOE_CLK_ENABLE();
  __HAL_RCC_GPIOH_CLK_ENABLE();
  __HAL_RCC_GPIOA_CLK_ENABLE();
  __HAL_RCC_GPIOC_CLK_ENABLE();
  __HAL_RCC_GPIOB_CLK_ENABLE();

  /*Configure GPIO pin Output Level */
  HAL_GPIO_WritePin(GPIOA, GPIO_PIN_4|GPIO_PIN_5|GPIO_PIN_6, GPIO_PIN_RESET);

  /*Configure GPIO pin Output Level */
  HAL_GPIO_WritePin(GPIOC, GPIO_PIN_5, GPIO_PIN_RESET);

  /*Configure GPIO pin Output Level */
  HAL_GPIO_WritePin(GPIOB, GPIO_PIN_0|GPIO_PIN_1, GPIO_PIN_RESET);

  /*Configure GPIO pins : PA4 PA5 PA6 */
  GPIO_InitStruct.Pin = GPIO_PIN_4|GPIO_PIN_5|GPIO_PIN_6;
  GPIO_InitStruct.Mode = GPIO_MODE_OUTPUT_PP;
  GPIO_InitStruct.Pull = GPIO_NOPULL;
  GPIO_InitStruct.Speed = GPIO_SPEED_FREQ_LOW;
  HAL_GPIO_Init(GPIOA, &GPIO_InitStruct);

  /*Configure GPIO pin : PC5 */
  GPIO_InitStruct.Pin = GPIO_PIN_5;
  GPIO_InitStruct.Mode = GPIO_MODE_OUTPUT_PP;
  GPIO_InitStruct.Pull = GPIO_NOPULL;
  GPIO_InitStruct.Speed = GPIO_SPEED_FREQ_LOW;
  HAL_GPIO_Init(GPIOC, &GPIO_InitStruct);

  /*Configure GPIO pins : PB0 PB1 */
  GPIO_InitStruct.Pin = GPIO_PIN_0|GPIO_PIN_1;
  GPIO_InitStruct.Mode = GPIO_MODE_OUTPUT_PP;
  GPIO_InitStruct.Pull = GPIO_NOPULL;
  GPIO_InitStruct.Speed = GPIO_SPEED_FREQ_LOW;
  HAL_GPIO_Init(GPIOB, &GPIO_InitStruct);

}

void Error_Handler(void)
{
  __disable_irq();
  while (1)
  {
  }
}
